# ET6801 register map
Vendor: ETMCU Inc.; File version: v0.0.1
CPU: CM7 r2p1, little endian, MPU, FPU, I-cache, D-cache, ITCM, DTCM, 4 interrupt priority bits
Registers are 32-bit, read-write, reset 0x0 unless marked. A register's access mark holds for its fields unless they carry their own. Offsets are from the block's base; [hi:lo] are bit positions; lines under a group give offsets from that group; {n}, {i} and the like mark numbered series; 'fields as' and 'values as' point back to an identical list.

## CLB — Provide an overview of the purpose and functionality of the peripheral: clb
Base 0x40022000
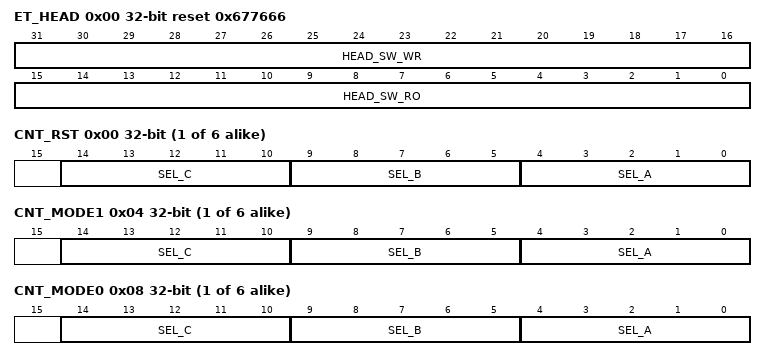
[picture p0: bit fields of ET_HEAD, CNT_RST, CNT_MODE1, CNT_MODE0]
0x00 ET_HEAD reset 0x677666
  [31:16] HEAD_SW_WR — 软件测试读写寄存器，硬件无访问
  [15:0] HEAD_SW_RO ro — 软件只读上报寄存器，硬件无访问,PID的ASICII 码表示
{0x4+0x12C*i} TILE_GRP[{i}] (i=0..5) group
  0x00 CNT_RST
    [14:10] SEL_C — CLB_CNT3模块计数器复位输入MUX选择信号。参见静态开关块输出多路复用表(CSB模块) 保护模式：EALLOW & LOCK 加载方式：静态加载
    [9:5] SEL_B — CLB_CNT2模块计数器复位输入MUX选择信号。参见静态开关块输出多路复用表(CSB模块) 保护模式：EALLOW & LOCK 加载方式：静态加载
    [4:0] SEL_A — CLB_CNT1模块计数器复位输入MUX选择信号。参见静态开关块输出多路复用表(CSB模块) 保护模式：EALLOW & LOCK 加载方式：静态加载
  0x04 CNT_MODE1
    [14:10] SEL_C — CLB_CNT3模块计数器Counter MODE_1输入MUX选择信号。参见静态开关块输出多路复用表(CSB模块) 保护模式：EALLOW & LOCK 加载方式：静态加载
    [9:5] SEL_B — CLB_CNT2模块计数器Counter MODE_1输入MUX选择信号。参见静态开关块输出多路复用表(CSB模块) 保护模式：EALLOW & LOCK 加载方式：静态加载
    [4:0] SEL_A — CLB_CNT1模块计数器Counter MODE_1输入MUX选择信号。参见静态开关块输出多路复用表(CSB模块) 保护模式：EALLOW & LOCK 加载方式：静态加载
  0x08 CNT_MODE0
    [14:10] SEL_C — CLB_CNT3模块计数器Counter MODE_0输入MUX选择信号。参见静态开关块输出多路复用表(CSB模块) 保护模式：EALLOW & LOCK 加载方式：静态加载
    [9:5] SEL_B — CLB_CNT2模块计数器Counter MODE_0输入MUX选择信号。参见静态开关块输出多路复用表(CSB模块) 保护模式：EALLOW & LOCK 加载方式：静态加载
    [4:0] SEL_A — CLB_CNT1模块计数器Counter MODE_0输入MUX选择信号。参见静态开关块输出多路复用表(CSB模块) 保护模式：EALLOW & LOCK 加载方式：静态加载
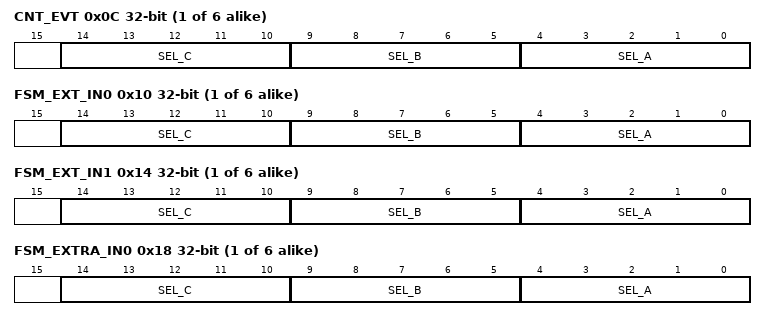
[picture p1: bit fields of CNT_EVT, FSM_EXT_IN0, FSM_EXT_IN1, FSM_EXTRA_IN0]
  0x0C CNT_EVT
    [14:10] SEL_C — CLB_CNT3模块计数器Counter EVENT输入MUX选择信号。参见静态开关块输出多路复用表(CSB模块) 保护模式：EALLOW & LOCK 加载方式：静态加载
    [9:5] SEL_B — CLB_CNT2模块计数器Counter EVENT输入MUX选择信号。参见静态开关块输出多路复用表(CSB模块) 保护模式：EALLOW & LOCK 加载方式：静态加载
    [4:0] SEL_A — CLB_CNT1模块计数器Counter EVENT输入MUX选择信号。参见静态开关块输出多路复用表(CSB模块) 保护模式：EALLOW & LOCK 加载方式：静态加载
  0x10 FSM_EXT_IN0
    [14:10] SEL_C — CLB_FSM3模块计数器FSM EXTERNAL_IN0输入MUX选择信号。参见静态开关块输出多路复用表(CSB模块) 保护模式：EALLOW & LOCK 加载方式：静态加载
    [9:5] SEL_B — CLB_ FSM 2模块计数器FSM EXTERNAL _IN0输入MUX选择信号。参见静态开关块输出多路复用表(CSB模块) 保护模式：EALLOW & LOCK 加载方式：静态加载
    [4:0] SEL_A — CLB_ FSM 1模块计数器FSM EXTERNAL _IN0输入MUX选择信号。参见静态开关块输出多路复用表(CSB模块) 保护模式：EALLOW & LOCK 加载方式：静态加载
  0x14 FSM_EXT_IN1
    [14:10] SEL_C — CLB_ FSM 3模块计数器FSM EXTERNAL_IN1输入MUX选择信号。参见静态开关块输出多路复用表(CSB模块) 保护模式：EALLOW & LOCK 加载方式：静态加载
    [9:5] SEL_B — CLB_ FSM 2模块计数器FSM EXTERNAL _IN1输入MUX选择信号。参见静态开关块输出多路复用表(CSB模块) 保护模式：EALLOW & LOCK 加载方式：静态加载
    [4:0] SEL_A — CLB_ FSM 1模块计数器FSM EXTERNAL _IN1输入MUX选择信号。参见静态开关块输出多路复用表(CSB模块) 保护模式：EALLOW & LOCK 加载方式：静态加载
  0x18 FSM_EXTRA_IN0
    [14:10] SEL_C — CLB_ FSM 3模块计数器FSM EXTRA_IN0输入MUX选择信号。参见静态开关块输出多路复用表(CSB模块) 保护模式：EALLOW & LOCK 加载方式：静态加载
    [9:5] SEL_B — CLB_ FSM 2模块计数器FSM EXTRA_IN0输入MUX选择信号。参见静态开关块输出多路复用表(CSB模块) 保护模式：EALLOW & LOCK 加载方式：静态加载
    [4:0] SEL_A — CLB_ FSM 1模块计数器FSM EXTRA_IN0输入MUX选择信号。参见静态开关块输出多路复用表(CSB模块) 保护模式：EALLOW & LOCK 加载方式：静态加载
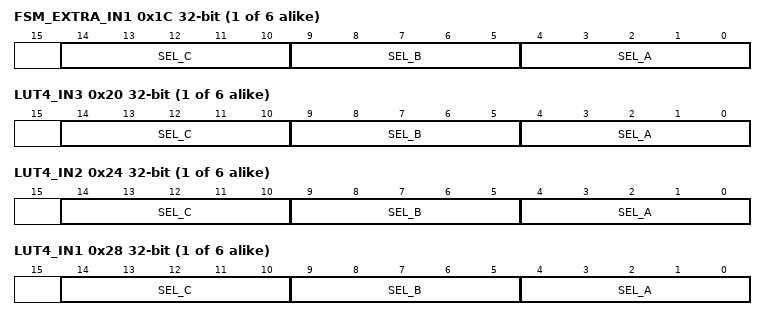
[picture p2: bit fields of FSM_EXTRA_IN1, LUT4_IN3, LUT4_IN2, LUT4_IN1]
  0x1C FSM_EXTRA_IN1
    [14:10] SEL_C — CLB_FSM3模块 EXTRA_IN1输入MUX选择信号。参见静态开关块输出多路复用表(CSB模块) 保护模式：EALLOW & LOCK 加载方式：静态加载
    [9:5] SEL_B — CLB_FSM2模块 EXTRA_IN1输入MUX选择信号。参见静态开关块输出多路复用表 保护模式：EALLOW & LOCK 加载方式：静态加载
    [4:0] SEL_A — CLB_FSM1模块 EXTRA_IN1输入MUX选择信号。参见静态开关块输出多路复用表(CSB模块) 保护模式：EALLOW & LOCK 加载方式：静态加载
  0x20 LUT4_IN3
    [14:10] SEL_C — CLB_LUT_3模块IN3输入MUX选择信号。参见静态开关块输出多路复用表(CSB模块) 保护模式：EALLOW & LOCK 加载方式：静态加载
    [9:5] SEL_B — CLB_LUT_2模块IN3输入MUX选择信号。参见静态开关块输出多路复用表(CSB模块) 保护模式：EALLOW & LOCK 加载方式：静态加载
    [4:0] SEL_A — CLB_LUT_1模块IN3输入MUX选择信号。参见静态开关块输出多路复用表(CSB模块) 保护模式：EALLOW & LOCK 加载方式：静态加载
  0x24 LUT4_IN2
    [14:10] SEL_C — CLB_LUT_3模块IN2输入MUX选择信号。参见静态开关块输出多路复用表 保护模式：EALLOW & LOCK 加载方式：静态加载
    [9:5] SEL_B — CLB_LUT_2模块IN2输入MUX选择信号。参见静态开关块输出多路复用表 保护模式：EALLOW & LOCK 加载方式：静态加载
    [4:0] SEL_A — CLB_LUT_1模块IN2输入MUX选择信号。参见静态开关块输出多路复用表 保护模式：EALLOW & LOCK 加载方式：静态加载
  0x28 LUT4_IN1
    [14:10] SEL_C — CLB_LUT_3模块IN1输入MUX选择信号。参见静态开关块输出多路复用表 保护模式：EALLOW & LOCK 加载方式：静态加载
    [9:5] SEL_B — CLB_LUT_2模块IN1输入MUX选择信号。参见静态开关块输出多路复用表 保护模式：EALLOW & LOCK 加载方式：静态加载
    [4:0] SEL_A — CLB_LUT_1模块IN1输入MUX选择信号。参见静态开关块输出多路复用表 保护模式：EALLOW & LOCK 加载方式：静态加载
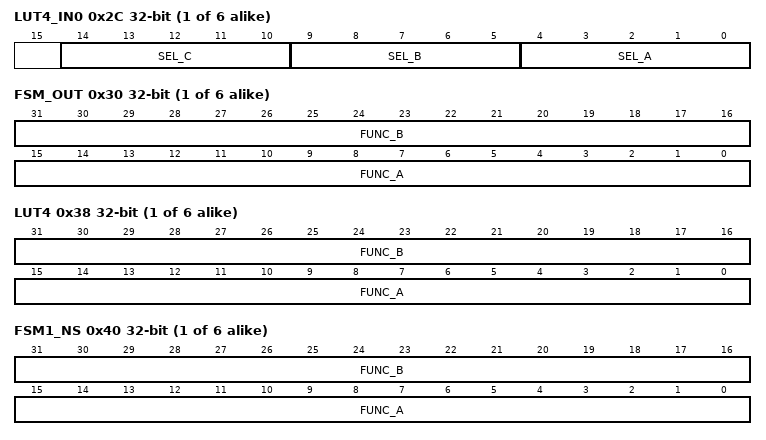
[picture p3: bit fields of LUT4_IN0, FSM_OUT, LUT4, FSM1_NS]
  0x2C LUT4_IN0
    [14:10] SEL_C — CLB_LUT_3模块IN0输入MUX选择信号。参见静态开关块输出多路复用表 保护模式：EALLOW & LOCK 加载方式：静态加载
    [9:5] SEL_B — CLB_LUT_2模块IN0输入MUX选择信号。参见静态开关块输出多路复用表 保护模式：EALLOW & LOCK 加载方式：静态加载
    [4:0] SEL_A — CLB_LUT_1模块IN0输入MUX选择信号。参见静态开关块输出多路复用表 保护模式：EALLOW & LOCK 加载方式：静态加载
  0x30 FSM_OUT
    [31:16] FUNC_B — CLB_FSM2模块OUTLUT输出函数配置 保护模式：EALLOW & LOCK 加载方式：静态加载
    [15:0] FUNC_A — CLB_FSM1模块OUTLUT输出函数配置 保护模式：EALLOW & LOCK 加载方式：静态加载
  0x34 FSM_OUT_FUNC
    [15:0] C — CLB_FSM3模块OUTLUT输出函数配置 保护模式：EALLOW & LOCK 加载方式：静态加载
  0x38 LUT4
    [31:16] FUNC_B — CLB_LUT2模块中输出函数配置 保护模式：EALLOW & LOCK 加载方式：静态加载
    [15:0] FUNC_A — CLB_LUT1模块中输出函数配置 保护模式：EALLOW & LOCK 加载方式：静态加载
  0x3C LUT4_FUNC
    [15:0] C — CLB_LUT3模块中输出函数配置 保护模式：EALLOW & LOCK 加载方式：静态加载
  0x40 FSM1_NS
    [31:16] FUNC_B — CLB_FSM1模块中 Nest State S1_LUT函数配置 保护模式：EALLOW & LOCK 加载方式：静态加载
    [15:0] FUNC_A — CLB_FSM1模块中 Nest State S0_LUT函数配置 保护模式：EALLOW & LOCK 加载方式：静态加载
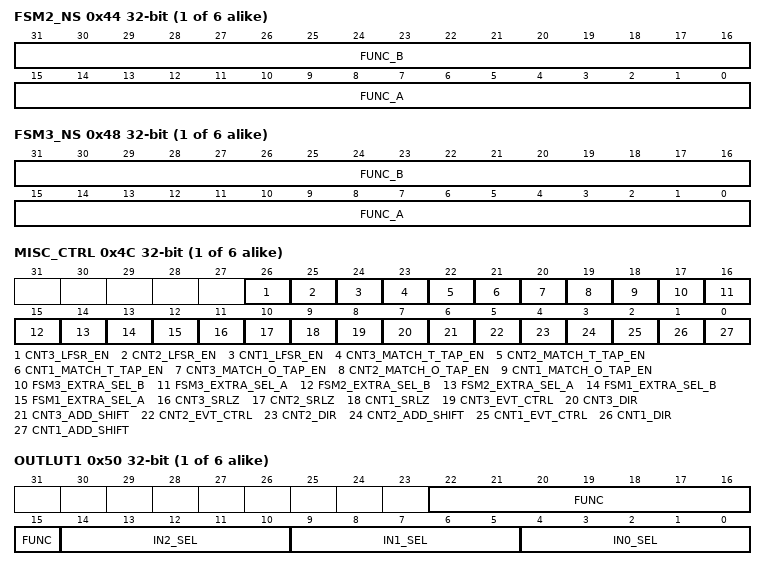
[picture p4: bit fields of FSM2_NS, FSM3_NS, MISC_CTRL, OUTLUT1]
  0x44 FSM2_NS
    [31:16] FUNC_B — CLB_FSM2模块中 Nest State S1_LUT函数配置 保护模式：EALLOW & LOCK 加载方式：静态加载
    [15:0] FUNC_A — CLB_FSM2模块中Nest State S0_LUT函数配置 保护模式：EALLOW & LOCK 加载方式：静态加载
  0x48 FSM3_NS
    [31:16] FUNC_B — CLB_FSM3模块中Nest State S1_LUT函数配置 保护模式：EALLOW & LOCK 加载方式：静态加载
    [15:0] FUNC_A — CLB_FSM3模块中Nest State S0_LUT函数配置 保护模式：EALLOW & LOCK 加载方式：静态加载
  0x4C MISC_CTRL
    [26] CNT3_LFSR_EN — 在计数器3为SERIALIZER模式的前提下，决定计数器是否为LFSR模式。 'b0 = 不采用LFSR模式 'b1 = 采用LFSR模式 保护模式：EALLOW & LOCK 加载方式：静态加载
    [25] CNT2_LFSR_EN — 在计数器2为SERIALIZER模式的前提下，决定计数器是否为LFSR模式。 'b0 = 不采用LFSR模式 'b1 = 采用LFSR模式 保护模式：EALLOW & LOCK 加载方式：静态加载
    [24] CNT1_LFSR_EN — 在计数器1为SERIALIZER模式的前提下，决定计数器是否为LFSR模式。 'b0 = 不采用LFSR模式 'b1 = 采用LFSR模式 保护模式：EALLOW & LOCK 加载方式：静态加载
    [23] CNT3_MATCH_T_TAP_EN — 决定计数器3 Match 2输出信号来源 'b0 =来自计数器和Match2 REF对比结果; 'b1 = 由match1_tap_val决定的计数器某个bit 保护模式：EALLOW & LOCK 加载方式：静态加载
    [22] CNT2_MATCH_T_TAP_EN — 决定计数器2 Match 2输出信号来源 'b0 =来自计数器和Match2 REF对比结果; 'b1 = 由match1_tap_val决定的计数器某个bit 保护模式：EALLOW & LOCK 加载方式：静态加载
    [21] CNT1_MATCH_T_TAP_EN — 决定计数器1 Match 2输出信号来源 'b0 =来自计数器和Match2 REF对比结果; 'b1 = 由match1_tap_val决定的计数器某个bit 保护模式：EALLOW & LOCK 加载方式：静态加载
    [20] CNT3_MATCH_O_TAP_EN — 决定计数器3 Match 1输出信号来源 'b0 =来自计数器和Match1 REF对比结果; 'b1 = 由match1_tap_val决定的计数器某个bit 保护模式：EALLOW & LOCK 加载方式：静态加载
    [19] CNT2_MATCH_O_TAP_EN — 决定计数器2 Match 1输出信号来源 'b0 =来自计数器和Match1 REF对比结果; 'b1 = 由match1_tap_val决定的计数器某个bit 保护模式：EALLOW & LOCK 加载方式：静态加载
    [18] CNT1_MATCH_O_TAP_EN — 决定计数器1 Match 1输出信号来源 'b0 =来自计数器和Match1 REF对比结果; 'b1 = 由match1_tap_val决定的计数器某个bit 保护模式：EALLOW & LOCK 加载方式：静态加载
    [17] FSM3_EXTRA_SEL_B — 选择FSM3 OUTLUT的输入信号 'b0 = FSM OUTLUT输入信号来自 S1; 'b1 = FSM OUTLUT输入信号来自EXTRA_EXT_IN1 保护模式：EALLOW & LOCK 加载方式：静态加载
    [16] FSM3_EXTRA_SEL_A — 选择FSM3 OUTLUT的输入信号 'b0 = FSM OUTLUT输入信号来自 S0; 'b1 = FSM OUTLUT输入信号来自EXTRA_EXT_IN0 保护模式：EALLOW & LOCK 加载方式：静态加载
    [15] FSM2_EXTRA_SEL_B — 选择FSM2 OUTLUT的输入信号 'b0 = FSM OUTLUT输入信号来自 S1; 'b1 = FSM OUTLUT输入信号来自EXTRA_EXT_IN1 保护模式：EALLOW & LOCK 加载方式：静态加载
    [14] FSM2_EXTRA_SEL_A — 选择FSM2 OUTLUT的输入信号 'b0 = FSM LUT输入信号来自 S0; 'b1 = FSM LUT输入信号来自EXTRA_EXT_IN0 保护模式：EALLOW & LOCK 加载方式：静态加载
    [13] FSM1_EXTRA_SEL_B — 选择FSM1 OUTLUT的输入信号 'b0 = FSM LUT输入信号来自 S1; 'b1 = FSM LUT输入信号来自EXTRA_EXT_IN1 保护模式：EALLOW & LOCK 加载方式：静态加载
    [12] FSM1_EXTRA_SEL_A — 选择FSM1 OUTLUT的输入信号 'b0 = FSM LUT输入信号来自 S0; 'b1 = FSM LUT输入信号来自EXTRA_EXT_IN0 保护模式：EALLOW & LOCK 加载方式：静态加载
    [11] CNT3_SRLZ — 控制CLB_CNT3模块计数器是否处于Serializer模式 'b0 = CLB_CNT3模块计数器不处于Serializer模式; 'b1 = CLB_CNT3模块计数器处于Serializer模式 保护模式：EALLOW & LOCK 加载方式：静态加载
    [10] CNT2_SRLZ — 控制CLB_CNT2模块计数器是否处于Serializer模式 'b0 = CLB_CNT2模块计数器不处于Serializer模式; 'b1 = CLB_CNT2模块计数器处于Serializer模式 保护模式：EALLOW & LOCK 加载方式：静态加载
    [9] CNT1_SRLZ — 控制CLB_CNT1模块计数器是否处于Serializer模式 'b0 = CLB_CNT1模块计数器不处于Serializer模式; 'b1 = CLB_CNT1模块计数器处于Serializer模式 保护模式：EALLOW & LOCK 加载方式：静态加载
    [8] CNT3_EVT_CTRL — 控制 CNT3 事件发生时计数器的操作。 'b0 = 不加法或移位，但加载预定义值 'b1 = 基于其他位，与预定义值相加/移位 保护模式：EALLOW & LOCK 加载方式：静态加载，该位必须为0，间接加载和计数器的HLC加载才能生效。
    [7] CNT3_DIR — 控制CNT3的加法/移位方向 'b0 = 右移或减去 'b1 = 左移或添加 保护模式：EALLOW & LOCK 加载方式：静态加载
    [6] CNT3_ADD_SHIFT — 控制CNT2计数器在事件发生时进行加法还是移位。 'b0 = 移位 'b1 = ADD 保护模式：EALLOW & LOCK 加载方式：静态加载
    [5] CNT2_EVT_CTRL — 控制 CNT2事件发生时计数器的操作。'b0 = 不加法或移位，但加载预定义值，此时为间接加载 'b1 = 基于其他位，与预定义值相加/移位 保护模式：EALLOW & LOCK 加载方式：静态，该位必须为0，间接加载和计数器的HLC加载才能生效。
    [4] CNT2_DIR — 控制CNT2的加法/移位方向 'b0 = 右移或减去 'b1 = 左移或添加 保护模式：EALLOW & LOCK 加载方式：静态加载
    [3] CNT2_ADD_SHIFT — 控制CNT1计数器在事件发生时进行加法还是移位。 'b0 = 移位 'b1 = ADD 保护模式：EALLOW & LOCK 加载方式：静态加载
    [2] CNT1_EVT_CTRL — 控制 CNT1事件发生时计数器的操作。 'b0 = 不加法或移位，但加载预定义值 'b1 = 基于其他位，与预定义值相加/移位 保护模式：EALLOW & LOCK 加载方式：静态，该位必须为0，间接加载和计数器的HLC加载才能生效。
    [1] CNT1_DIR — 控制 CNT1 的加法/移位方向 'b0 = 右移或减去 'b1 = 左移或添加 保护模式：EALLOW &LOCK 加载方式：静态加载
    [0] CNT1_ADD_SHIFT — 控制CLB_CNT1模块计数器在事件发生时进行加法还是移位。 'b0 = 移位 'b1 = ADD 保护模式：EALLOW & LOCK 加载方式：静态加载
  0x50 OUTLUT1
    [22:15] FUNC — outputLUT输出函数
    [14:10] IN2_SEL — outputLUT_IN2 MUX选择信号。参见静态开关块输出多路复用表 保护模式：EALLOW & LOCK 加载方式：静态加载
    [9:5] IN1_SEL — outputLUT_IN1 MUX选择信号。参见静态开关块输出多路复用表 保护模式：EALLOW & LOCK 加载方式：静态加载
    [4:0] IN0_SEL — outputLUT_IN0 MUX选择信号。参见静态开关块输出多路复用表 保护模式：EALLOW & LOCK 加载方式：静态加载
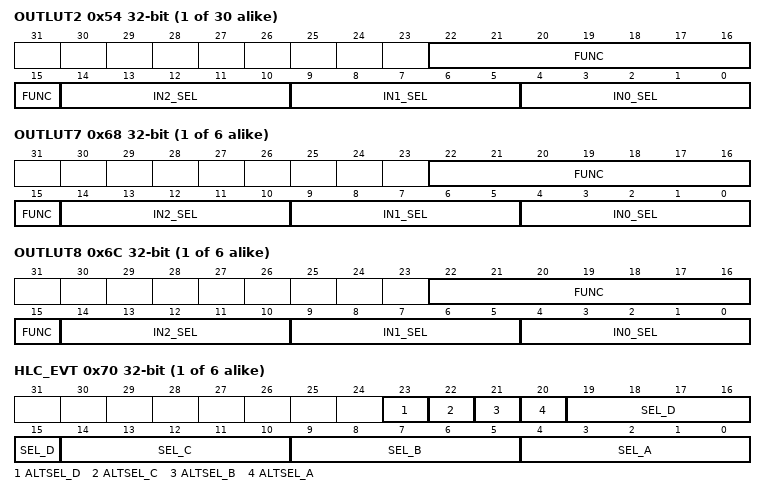
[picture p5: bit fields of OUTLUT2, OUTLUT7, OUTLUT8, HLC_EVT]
  {0x4C+4j} OUTLUT{j} (j=2..6)
    [22:15] FUNC — outputLUT输出函数
    [14:10] IN2_SEL — outputLUT{j}_IN2 MUX选择信号。参见静态开关块输出多路复用表 保护模式：EALLOW & LOCK 加载方式：静态加载
    [9:5] IN1_SEL — outputLUT{j}_IN1 MUX选择信号。参见静态开关块输出多路复用表 保护模式：EALLOW & LOCK 加载方式：静态加载
    [4:0] IN0_SEL — outputLUT{j}_IN0 MUX选择信号。参见静态开关块输出多路复用表 保护模式：EALLOW & LOCK 加载方式：静态加载
  0x68 OUTLUT7
    fields as TILE_GRP[0].OUTLUT1
  0x6C OUTLUT8
    fields as TILE_GRP[0].OUTLUT1
  0x70 HLC_EVT
    [23] ALTSEL_D — EVENT3另一组选择信号 'b0 = 从静态开关复用表中选择 'b1 = 从静态开关复用备选表中选择 保护模式：EALLOW & LOCK
    [22] ALTSEL_C — EVENT2另一组选择信号 'b0 = 从静态开关复用表中选择 'b1 = 从静态开关复用备选表中选择 保护模式：EALLOW & LOCK
    [21] ALTSEL_B — EVENT1另一组选择信号 'b0 = 从静态开关复用表中选择 'b1 = 从静态开关复用备选表中选择 保护模式：EALLOW & LOCK
    [20] ALTSEL_A — EVENT0另一组选择信号 'b0 = 从静态开关复用表中选择 'b1 = 从静态开关复用备选表中选择 保护模式：EALLOW & LOCK
    [19:15] SEL_D — HLC EVENT3输入MUX选择信号。参见静态开关块输出多路复用表 保护模式：EALLOW & LOCK 加载方式：静态加载
    [14:10] SEL_C — HLC EVENT2输入MUX选择信号。参见静态开关块输出多路复用表 保护模式：EALLOW & LOCK 加载方式：静态加载
    [9:5] SEL_B — HLC EVENT1输入MUX选择信号。参见静态开关块输出多路复用表 保护模式：EALLOW & LOCK 加载方式：静态加载
    [4:0] SEL_A — HLC EVENT0输入MUX选择信号。参见静态开关块输出多路复用表 保护模式：EALLOW & LOCK 加载方式：静态加载
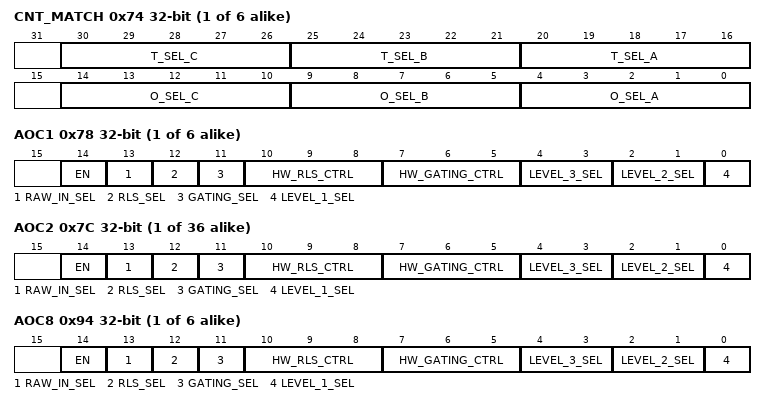
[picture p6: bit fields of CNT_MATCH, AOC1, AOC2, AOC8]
  0x74 CNT_MATCH
    [30:26] T_SEL_C — match2选择计数器2某一比特作为输出的MUX选择信号。 match1 = cnt1[cfg_cnt_match_t_sel_c]; 保护模式：EALLOW & LOCK 加载方式：静态加载
    [25:21] T_SEL_B — match2选择计数器1某一比特作为输出的MUX选择信号。 match1 = cnt1[cfg_cnt_match_t_sel_b]; 保护模式：EALLOW & LOCK 加载方式：静态加载
    [20:16] T_SEL_A — match2选择计数器0某一比特作为输出的MUX选择信号。 match1 = cnt1[cfg_cnt_match_t_sel_a]; 保护模式：EALLOW & LOCK 加载方式：静态加载
    [14:10] O_SEL_C — match1选择计数器2某一比特作为输出的MUX选择信号。 match1 = cnt1[cfg_cnt_match_o_sel_c]; 保护模式：EALLOW & LOCK 加载方式：静态加载
    [9:5] O_SEL_B — match1选择计数器1某一比特作为输出的MUX选择信号。 match1 = cnt1[cfg_cnt_match_o_sel_b]; 保护模式：EALLOW & LOCK 加载方式：静态加载
    [4:0] O_SEL_A — match1选择计数器0某一比特作为输出的MUX选择信号, match1 = cnt1[cfg_cnt_match_o_sel_a]; 保护模式：EALLOW & LOCK 加载方式：静态加载
  0x78 AOC1
    [14] EN — 选择CELL_output输入信号经过AOC多级处理或者直接bypass 'b0 = bypass 'b1 = enable AOC模块 加载方式：动态加载
    [13] RAW_IN_SEL — 选择AOC1模块的输入 'b0 = outlut_output1（打一拍）作为输入 'b1 =bdry_in_a作为输入 保护模式：EALLOW & LOCK 加载方式：动态加载
    [12] RLS_SEL — 选择HW(CELL outputs)或SW(GP_REG)作为release的控制信号 'b0 = SW寄存器值作为release的控制信号 'b1 = CELL outputs作为release控制信号 保护模式：EALLOW & LOCK 加载方式：动态加载
    [11] GATING_SEL — 选择HW(CELL outputs)或SW(GP_REG)作为gating的控制信号 'b0 = SW寄存器值作为gating的控制信号 'b1 = CELL outputs作为gating控制信号 保护模式：EALLOW & LOCK 加载方式：动态加载
    [10:8] HW_RLS_CTRL — AOC level3 阶段选择1bit CLB_OUTLUT作为控制信号。 该值从0到7分别对应outlut1~8的输出 加载方式：静态加载
    [7:5] HW_GATING_CTRL — AOC level2 阶段选择1bit CLB_OUTLUT作为控制信号。 该值从0到7分别对应outlut1~8的输出 保护模式：EALLOW & LOCK 加载方式：静态加载
    [4:3] LEVEL_3_SEL — 第二级MUX选择信号。 'b00 = 原信号输出 'b01 = 输入控制信号拉高会导致输出的清除 'b10= 输入控制信号的上升沿会导致输出的置位 'b11 = 输入信号打一拍后输出 保护模式：EALLOW & LOCK 加载方式：静态加载
    [2:1] LEVEL_2_SEL — 第二级MUX选择信号。 'b00 = 原信号输入至下一级 'b01 = (上一级输入信号&gating_control ) 输入至下一级 'b10= (上一级输入信号|gating_control ) 输入至下一级 'b11 = (上一级输入信号^gating_control )输入至下一级 保护模式：EALLOW & LOCK 加载方式：静态加载
    [0] LEVEL_1_SEL — 第一级MUX选择信号。 'b0 = 原信号输入至下一级 'b1 = 信号翻转后输入至下一级 保护模式：EALLOW & LOCK 加载方式：静态加载
  {0x74+4j} AOC{j} (j=2..7)
    [14] EN — 选择CELL_output输入信号经过AOC多级处理或者直接bypass 'b0 = bypass 'b1 = enable AOC模块 加载方式：动态加载
    [13] RAW_IN_SEL — 选择AOC模块的输入 'b0 = CELL_output（打一拍）作为输入 'b1 = CELL inputs作为输入 保护模式：EALLOW & LOCK 加载方式：动态加载
    [12] RLS_SEL — 选择HW(CELL outputs)或SW(GP_REG)作为release的控制信号 'b0 = SW寄存器值作为release的控制信号 'b1 = CELL outputs作为release控制信号 保护模式：EALLOW & LOCK 加载方式：动态加载
    [11] GATING_SEL — 选择HW(CELL outputs)或SW(GP_REG)作为gating的控制信号 'b0 = SW寄存器值作为gating的控制信号 'b1 = CELL outputs作为gating控制信号 保护模式：EALLOW & LOCK 加载方式：动态加载
    [10:8] HW_RLS_CTRL — AOC level3 阶段选择1bit CLB_OUTLUT作为控制信号。 该值从0到7分别对应outlut1~8的输出 加载方式：静态加载
    [7:5] HW_GATING_CTRL — AOC level2 阶段选择1bit CLB_OUTLUT作为控制信号。 该值从0到7分别对应outlut1~8的输出 保护模式：EALLOW & LOCK 加载方式：静态加载
    [4:3] LEVEL_3_SEL — 第二级MUX选择信号。 'b00 = 原信号输出 'b01 = 输入控制信号拉高会导致输出的清除 'b10= 输入控制信号的上升沿会导致输出的置位 'b11 = 输入信号打一拍后输出 保护模式：EALLOW & LOCK 加载方式：静态加载
    [2:1] LEVEL_2_SEL — 第二级MUX选择信号。 'b00 = 原信号输入至下一级 'b01 = (上一级输入信号&gating_control ) 输入至下一级 'b10= (上一级输入信号|gating_control ) 输入至下一级 'b11 = (上一级输入信号^gating_control )输入至下一级 保护模式：EALLOW & LOCK 加载方式：静态加载
    [0] LEVEL_1_SEL — 第一级MUX选择信号。 'b0 = 原信号输入至下一级 'b1 = 信号翻转后输入至下一级 保护模式：EALLOW & LOCK 加载方式：静态加载
  0x94 AOC8
    [14] EN — 选择CELL_output输入信号经过AOC多级处理或者直接bypass 'b0 = bypass 'b1 = enable AOC模块 加载方式：静态加载
    [13] RAW_IN_SEL — 选择AOC模块的输入 'b0 = CELL_output（打一拍）作为输入 'b1 = CELL inputs作为输入 保护模式：EALLOW & LOCK 加载方式：静态加载
    [12] RLS_SEL — 选择HW(CELL outputs)或SW(GP_REG)作为release的控制信号 'b0 = SW寄存器值作为release的控制信号 'b1 = CELL outputs作为release控制信号 保护模式：EALLOW & LOCK 加载方式：静态加载
    [11] GATING_SEL — 选择HW(TILE outputs)或SW作为gating的控制信号 'b0 = SW寄存器值作为gating的控制信号 'b1 = TILE outputs作为gating控制信号 保护模式：EALLOW & LOCK 加载方式：静态加载
    [10:8] HW_RLS_CTRL — 从8个CLB_OUTLUT中选择一个作为rls的控制信号； 'b000 = clb_outlut1_output 'b001 = clb_outlut2_output ... 'b111 = clb_outlut8_output 保护模式：EALLOW & LOCK 加载方式：静态加载
    [7:5] HW_GATING_CTRL — 从8个CLB_OUTLUT中选择一个作为gating的控制信号； 'b000 = clb_outlut1_output 'b001 = clb_outlut2_output ... 'b111 = clb_outlut8_output 保护模式：EALLOW & LOCK 加载方式：静态加载
    [4:3] LEVEL_3_SEL — 第二级MUX选择信号。 'b00 = 原信号输出 'b01 = 输入控制信号拉高会导致输出的清除 'b10= 输入控制信号的上升沿会导致输出的置位 'b11 = 输入信号打一拍后输出 保护模式：EALLOW & LOCK 加载方式：静态加载
    [2:1] LEVEL_2_SEL — 第二级MUX选择信号。 'b00 = 原信号输入至下一级 'b01 = (上一级输入信号&gating_control ) 输入至下一级 'b10= (上一级输入信号|gating_control ) 输入至下一级 'b11 = (上一级输入信号^gating_control )输入至下一级 保护模式：EALLOW & LOCK 加载方式：静态加载
    [0] LEVEL_1_SEL — 第一级MUX选择信号。 'b0 = 原信号输入至下一级 'b1 = 信号翻转后输入至下一级 保护模式：EALLOW & LOCK 加载方式：静态加载
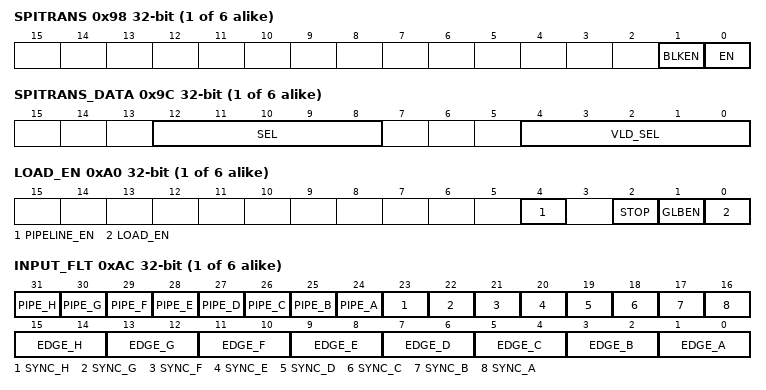
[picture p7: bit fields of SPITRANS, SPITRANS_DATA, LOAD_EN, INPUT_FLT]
  0x98 SPITRANS
    [1] BLKEN — 该阻止对CFG_CLB_OUT_EN的写入； 'b0 = CFG_CLB_OUT_EN起作用； 'b1 = CFG_CLB_OUT_EN被屏蔽； 保护模式：EALLOW & LOCK 加载方式：静态加载
    [0] EN — 使能SPI_DataTrans模式； 'b0 = 不使能 'b1 = 使能通用寄存器GR_A的值可以传输到SPIbuffer中 保护模式：EALLOW & LOCK 加载方式：静态加载
  0x9C SPITRANS_DATA
    [12:8] SEL — 选择R0发送到SPIbuffer的16比特数据； 'b 00000 Output data is R0[15:0] 'b 00001 Output data is R0[16:1] 'b 00010 Output data is R0[17:2] 'b 00011 Output data is R0[18:3] ... 保护模式：EALLOW & LOCK 加载方式：静态加载
    [4:0] VLD_SEL — 在CSB中选择一个信号作为将GR_A数据发送到SPIbuffer的数据有效信号，参见静态开关块输出多路复用表 保护模式：EALLOW & LOCK 加载方式：静态加载
  0xA0 LOAD_EN
    [4] PIPELINE_EN — 该位计数器模块中的pipelining模式，不开启时，计数器模块执行加法时为load+cnt_val；开启后计数器执行加法为load+last_cnt_val，并在下一拍写入计数器寄存器中。 设置为1使能流水操作 保护模式：无 加载方式：静态加载
    [2] STOP — 该位定义 CPU 调试 HALT 期间 CELL 中sequential elements的行为。如果该位设置为 0，则调试 HALT 条件被忽略 'b0 = CLB正常运行 'b1 = CLB内部运算暂停； 保护模式：无 加载方式：动态加载
    [1] GLBEN — 该位是 CELL 逻辑的全局使能信号。这也是 CELL 逻辑的软复位。当该位从 1 清零到 0 时，CLB 输出（包括 LUT 和 OUTLUT）将被门控，即当 GLOBAL_EN 为低电平时，CLB 输出为低电平。此外，FSM 和 AOC 块也将被重置。需要注意的是，当该位变为低电平时，COUNTER 模块和 HLC 将停止运行，但内部不会重置。这样就可以在 GLOBAL_EN 为 0 时预载这些子模块。全局使能在完成所有其他配置设置。 保护模式：LOCK 加载方式：动态加载
    [0] LOAD_EN — 将该位设置为 "1 "时，将产生一个脉冲使能tile中的 间接寄存器 加载数据 保护模式：无 加载方式：动态加载
  0xA4 LOAD_ADDR
    [5:0] VALUE — 间接加载时的地址。 保护模式：无 加载方式：动态加载
  0xA8 LOAD_DATA
    [31:0] VALUE — 间接加载时的数据。 保护模式：无 加载方式：动态加载
  0xAC INPUT_FLT
    [31] PIPE_H — CELL INPUT[7] pipeline 'b0 = bypass 'b1 = 输入信号经过flop被打一拍 保护模式：LOCK 加载方式：静态加载
    [30] PIPE_G — CELL INPUT[6] pipeline 'b0 = bypass 'b1 = 输入信号经过flop被打一拍 保护模式：LOCK 加载方式：静态加载
    [29] PIPE_F — CELL INPUT[5] pipeline 'b0 = bypass 'b1 = 输入信号经过flop被打一拍 保护模式：LOCK 加载方式：静态加载
    [28] PIPE_E — CELL INPUT[4] pipeline 'b0 = bypass 'b1 = 输入信号经过flop被打一拍 保护模式：LOCK 加载方式：静态加载
    [27] PIPE_D — CELL INPUT[3] pipeline 'b0 = bypass 'b1 = 输入信号经过flop被打一拍 保护模式：LOCK 加载方式：静态加载
    [26] PIPE_C — CELL INPUT[2] pipeline 'b0 = bypass 'b1 = 输入信号经过flop被打一拍 保护模式：LOCK 加载方式：静态加载
    [25] PIPE_B — CELL INPUT[1] pipeline 'b0 = bypass 'b1 = 输入信号经过flop被打一拍 保护模式：LOCK 加载方式：静态加载
    [24] PIPE_A — CELL INPUT[0] pipeline 'b0 = bypass 'b1 = 输入信号经过flop被打一拍 保护模式： LOCK 加载方式：静态加载
    [23] SYNC_H — CELL INPUT[7] 同步器控制 'b0 = bypass 'b1 = 输入信号被同步处理 保护模式：LOCK 加载方式：静态加载
    [22] SYNC_G — CELL INPUT[6] 同步器控制 'b0 = bypass 'b1 = 输入信号被同步处理 保护模式：LOCK 加载方式：静态加载
    [21] SYNC_F — CELL INPUT[5] 同步器控制 'b0 = bypass 'b1 = 输入信号被同步处理 保护模式：LOCK 加载方式：静态加载
    [20] SYNC_E — CELL INPUT[4] 同步器控制 'b0 = bypass 'b1 = 输入信号被同步处理 保护模式：LOCK 加载方式：静态加载
    [19] SYNC_D — CELL INPUT[3] 同步器控制 'b0 = bypass 'b1 = 输入信号被同步处理 保护模式：LOCK 加载方式：静态加载
    [18] SYNC_C — CELL INPUT[2] 同步器控制 'b0 = bypass 'b1 = 输入信号被同步处理 保护模式：LOCK 加载方式：静态加载
    [17] SYNC_B — CELL INPUT[1] 同步器控制 'b0 = bypass 'b1 = 输入信号被同步处理 保护模式：LOCK 加载方式：静态加载
    [16] SYNC_A — CELL INPUT[0] 同步器控制 'b0 = bypass 'b1 = 输入信号被同步处理 保护模式：LOCK 加载方式：静态加载
    [15:14] EDGE_H — CELL INPUT[7] filter选择，用于边沿检测 'b00 = bypass 'b01 = 上升沿检测 'b10 = 下降沿检测 'b11 = 边沿检测 保护模式：LOCK 加载方式：静态加载
    [13:12] EDGE_G — CELL INPUT[6] filter选择，用于边沿检测 'b00 = bypass 'b01 = 上升沿检测 'b10 = 下降沿检测 'b11 = 边沿检测 保护模式：LOCK 加载方式：静态加载
    [11:10] EDGE_F — CELL INPUT[5] filter选择，用于边沿检测 'b00 = bypass 'b01 = 上升沿检测 'b10 = 下降沿检测 'b11 = 边沿检测 保护模式：LOCK 加载方式：静态加载
    [9:8] EDGE_E — CELL INPUT[4] filter选择，用于边沿检测 'b00 = bypass 'b01 = 上升沿检测 'b10 = 下降沿检测 'b11 = 边沿检测 保护模式：LOCK 加载方式：静态加载
    [7:6] EDGE_D — CELL INPUT[3] filter选择，用于边沿检测 'b00 = bypass 'b01 = 上升沿检测 'b10 = 下降沿检测 'b11 = 边沿检测 保护模式：LOCK 加载方式：静态加载
    [5:4] EDGE_C — CELL INPUT[2] filter选择，用于边沿检测 'b00 = bypass 'b01 = 上升沿检测 'b10 = 下降沿检测 'b11 = 边沿检测 保护模式：LOCK 加载方式：静态加载
    [3:2] EDGE_B — CELL INPUT[1] filter选择，用于边沿检测 'b00 = bypass 'b01 = 上升沿检测 'b10 = 下降沿检测 'b11 = 边沿检测 保护模式：LOCK 加载方式：静态加载
    [1:0] EDGE_A — CELL INPUT[0] filter选择，边沿检测 'b00 = bypass 'b01 = 上升沿检测 'b10 = 下降沿检测 'b11 = 边沿检测 保护模式：LOCK 加载方式：静态加载
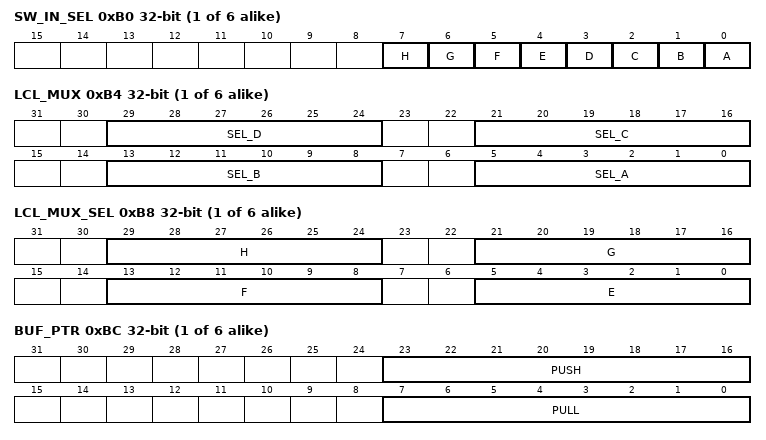
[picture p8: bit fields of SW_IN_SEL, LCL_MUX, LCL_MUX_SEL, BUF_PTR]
  0xB0 SW_IN_SEL
    [7] H — 选择CELL INPUT[7]来自外部输入还是来自CFG_SW[7] 'b0 = 来自外部输入 'b1 = 来自cfg_sw_input_h 保护模式：LOCK 加载方式：静态加载
    [6] G — 选择CELL INPUT[6]来自外部输入还是来自CFG_SW[6] 'b0 = 来自外部输入 'b1 = 来自cfg_sw_input_g 保护模式：LOCK 加载方式：静态加载
    [5] F — 选择CELL INPUT[5]来自外部输入还是来自CFG_SW[5] 'b0 = 来自外部输入 'b1 = 来自cfg_sw_input_f 保护模式：LOCK 加载方式：静态加载
    [4] E — 选择CELL INPUT[4]来自外部输入还是来自软件输入； 'b0 = 来自外部输入 'b1 = 来自cfg_sw_input_e 保护模式：LOCK 加载方式：静态加载
    [3] D — 选择CELL INPUT[3]来自外部输入还是来自软件输入； 'b0 = 来自外部输入 'b1 = 来自cfg_sw_input_d 保护模式：LOCK 加载方式：静态加载
    [2] C — 选择CELL INPUT[2]来自外部输入还是来自软件输入； 'b0 = 来自外部输入 'b1 = 来自cfg_sw_input_c 保护模式：LOCK 加载方式：静态加载
    [1] B — 选择CELL INPUT[1]来自外部输入还是来自软件输入； 'b0 = 来自外部输入 'b1 = 来自cfg_sw_input_b 保护模式：LOCK 加载方式：静态加载
    [0] A — 选择CELL INPUT[0]来自外部输入还是来自软件输入； 'b0 = 来自外部输入 'b1 = 来自cfg_sw_input_a 保护模式：LOCK 加载方式：静态加载
  0xB4 LCL_MUX
    [29:24] SEL_D — INPUT3 6比特MUX选择信号，参见本地信号多路复用表 保护模式：LOCK 加载方式：静态加载
    [21:16] SEL_C — INPUT2 6比特MUX选择信号，参见本地信号多路复用表 保护模式：LOCK 加载方式：静态加载
    [13:8] SEL_B — INPUT1 6比特MUX选择信号，参见本地信号多路复用表 保护模式：LOCK 加载方式：静态加载
    [5:0] SEL_A — INPUT0 6比特MUX选择信号，参见本地信号多路复用表 保护模式：LOCK 加载方式：静态加载
  0xB8 LCL_MUX_SEL
    [29:24] H — INPUT3 6比特MUX选择信号，参见本地信号多路复用表 保护模式：LOCK 加载方式：静态加载
    [21:16] G — INPUT2 6比特MUX选择信号，参见本地信号多路复用表 保护模式：LOCK 加载方式：静态加载
    [13:8] F — INPUT1 6比特MUX选择信号，参见本地信号多路复用表 保护模式：LOCK 加载方式：静态加载
    [5:0] E — INPUT0 6比特MUX选择信号，参见本地信号多路复用表 保护模式：LOCK 加载方式：静态加载
  0xBC BUF_PTR
    [23:16] PUSH — clb_tile数据交换模块的fifo指针。push表示从HLC模块写入到4-word fifo。到达0xff归零其中低2比特表示操作中的实际指针。
    [7:0] PULL — 数据交换模块的fifo指针。pull表示从4-word fifo写入到HLC模块。
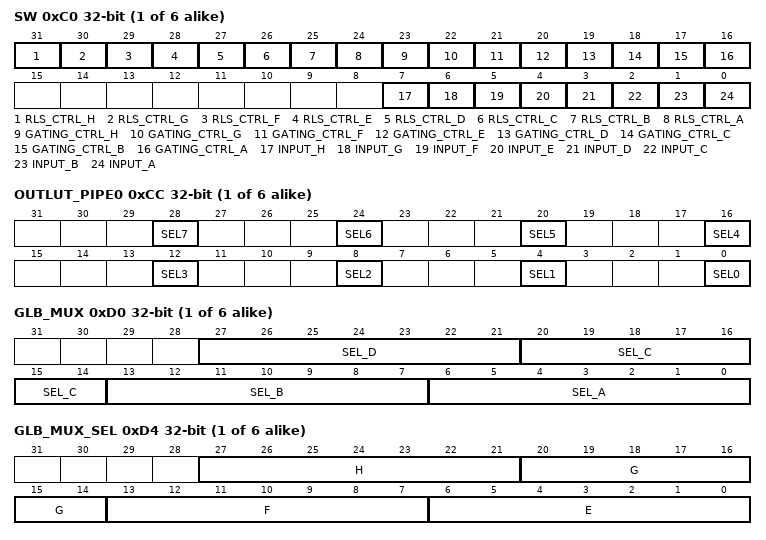
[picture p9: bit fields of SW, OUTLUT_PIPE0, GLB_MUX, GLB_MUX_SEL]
  0xC0 SW
    [31] RLS_CTRL_H — AOC8模块中output1软件release控制 保护模式：无 加载方式：动态加载
    [30] RLS_CTRL_G — AOC7模块中output1软件release控制 保护模式：无 加载方式：动态加载
    [29] RLS_CTRL_F — AOC6模块中output1软件release控制 保护模式：无 加载方式：动态加载
    [28] RLS_CTRL_E — AOC5模块中output1软件release控制 保护模式：无 加载方式：动态加载
    [27] RLS_CTRL_D — AOC4模块中output1软件release控制 保护模式：无 加载方式：动态加载
    [26] RLS_CTRL_C — AOC3模块中output1软件release控制 保护模式：无 加载方式：动态加载
    [25] RLS_CTRL_B — AOC2模块中output1软件release控制 保护模式：无 加载方式：动态加载
    [24] RLS_CTRL_A — AOC1模块中output软件release控制 保护模式：无 加载方式：动态加载
    [23] GATING_CTRL_H — AOC模块中output软件gating 控制 保护模式：无 加载方式：动态加载
    [22] GATING_CTRL_G — AOC模块中outpu软件gating 控制 保护模式：无 加载方式：动态加载
    [21] GATING_CTRL_F — AOC模块中outpu软件gating 控制 保护模式：无 加载方式：动态加载
    [20] GATING_CTRL_E — AOC模块中outpu软件gating 控制 保护模式：无 加载方式：动态加载
    [19] GATING_CTRL_D — AOC模块中outpu软件gating 控制 保护模式：无 加载方式：动态加载
    [18] GATING_CTRL_C — AOC模块中outpu软件gating 控制 保护模式：无 加载方式：动态加载
    [17] GATING_CTRL_B — AOC模块中output1软件gating 控制 保护模式：无 加载方式：动态加载
    [16] GATING_CTRL_A — AOC模块中output1软件gating 控制 保护模式：无 加载方式：动态加载
    [7] INPUT_H — CPU配置的值，由cfg_clb_in_sel_h选择可直接作为CLB模块clb_bdry_in_h的输入 保护模式：无 加载方式：动态加载
    [6] INPUT_G — CPU配置的值，由cfg_clb_in_sel_h选择可直接作为CLB模块clb_bdry_in_h的输入 保护模式：无 加载方式：动态加载
    [5] INPUT_F — CPU配置的值，由cfg_clb_in_sel_h选择可直接作为CLB模块clb_bdry_in_h的输入 保护模式：无 加载方式：动态加载
    [4] INPUT_E — CPU配置的值，由cfg_clb_in_sel_h选择可直接作为CLB模块clb_bdry_in_h的输入 保护模式：无 加载方式：动态加载
    [3] INPUT_D — CPU配置的值，由cfg_clb_in_sel_h选择可直接作为CLB模块clb_bdry_in_h的输入 保护模式：无 加载方式：动态加载
    [2] INPUT_C — CPU配置的值，由cfg_clb_in_sel_c选择可直接作为CLB模块clb_bdry_in_c的输入 保护模式：无 加载方式：动态加载
    [1] INPUT_B — CPU配置的值，由cfg_clb_in_sel_b选择可直接作为CLB模块clb_bdry_in_b的输入 保护模式：无 加载方式：动态加载
    [0] INPUT_A — CPU配置的值，由cfg_clb_in_sel_a选择可直接作为CLB模块clb_bdry_in_a的输入 保护模式：无 加载方式：动态加载
  0xC4 OUT
    [31:0] EN — CLB输出信号使能，对于每一bit： 'b0 = peripheral 信号pass through原来的路径 'b1 =CLB边界输出替换对应的外设信号，发送往外设原先的目的地； 保护模式：无 加载方式：静态加载
  0xC8 OUT_1D
    [9:0] SEL — 边界输出是否打一拍后发送到对应目的地；对于每一bit： 'b0 = 每个tile的输出bypass，发送往全局信号列表/XBARs; 'b1 = 每个tile的输出打一拍后，发送往全局信号列表/XBARs 保护模式：无 加载方式：静态加载
  0xCC OUTLUT_PIPE0
    [4n] SEL{n} (n=0..7) — 发送到OUTPUTLUT{n}的CSB选择前信号是否打拍； 信号包含： fsm0_output，lut0_output，fsm1_output lut1_output，fsm2_output，lut2_output 'b0 =bypass，适用异步信号直接发送到IO; 'b1 = 打一拍；同步信号需要选择该项； 保护模式：无 加载方式：静态加载
  0xD0 GLB_MUX
    [27:21] SEL_D — INPUT_D 7比特Global MUX选择信号，参见本地信号多路复用表 保护模式：LOCK 加载方式：静态加载
    [20:14] SEL_C — INPUT_C 7比特Global MUX选择信号，参见本地信号多路复用表 保护模式：LOCK 加载方式：静态加载
    [13:7] SEL_B — INPUT_B 7比特Global MUX选择信号，参见本地信号多路复用表 保护模式：LOCK 加载方式：静态加载
    [6:0] SEL_A — INPUT_A 7比特Global MUX选择信号，参见全局信号多路复用表 保护模式：LOCK 加载方式：静态加载
  0xD4 GLB_MUX_SEL
    [27:21] H — INPUT_H 7比特Global MUX选择信号，参见本地信号多路复用表 保护模式：LOCK 加载方式：静态加载
    [20:14] G — INPUT_G 7比特Global MUX选择信号，参见本地信号多路复用表 保护模式：LOCK 加载方式：静态加载
    [13:7] F — INPUT_F 7比特Global MUX选择信号，参见本地信号多路复用表 保护模式：LOCK 加载方式：静态加载
    [6:0] E — INPUT_E 7比特Global MUX选择信号，参见全局信号多路复用表 保护模式：LOCK 加载方式：静态加载
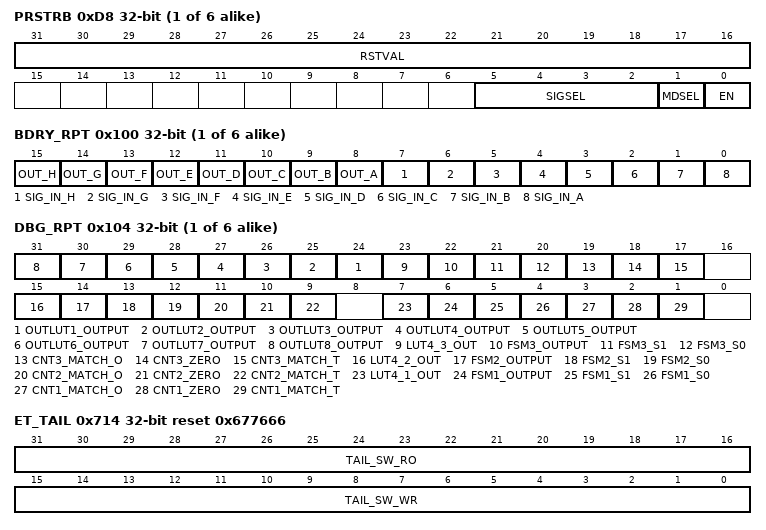
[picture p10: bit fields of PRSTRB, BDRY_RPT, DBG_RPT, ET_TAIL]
  0xD8 PRSTRB
    [31:16] RSTVAL — 当PRSTRB模块内16bit计数器达到该值时复位到0； 保护模式：LOCK 加载方式：静态加载
    [5:2] SIGSEL — MUX选择信号，选取计数器某一比特信号，例如 'b0000 = 选择计数器比特0，实际上对应时钟2分频 'b0001 = 选择计数器比特1，实际上对应时钟4分频 ... 'b1111 = 选择计数器比特15，实际上对应时钟2^16分频 保护模式：LOCK 加载方式：静态加载
    [1] MDSEL — clk/strobe选择信号 'b0 = prescale模块输出strobe。当计数器值等于prescale_value时产生strobe; 'b1 = 输出tap信号选择的计数器某位bit信号 保护模式：LOCK 加载方式：静态加载
    [0] EN — 使能预分频clk/strobe发生器 16 位计数器用于产生strobe或向 CLB CELL 发送选定的计数器位bit。通过一个 LCL_IN MUX 端口把strobe/预分频clk发送到 Tile，Tile 逻辑可根据需要选用。 clk/strobe选择信号 'b0 = prstrb模块输出为0；同时模块内计数器暂复位为0 'b1 = 输出tap信号选择的计数器某位bit信号 保护模式：LOCK 加载方式：静态加载
  0xDC HLC_INST_ADDR_RPT ro
    [4:0] VALUE — 用于读取instruction mem 值的地址指针 保护模式：无
  0xE0 HLC_INST_RPT ro
    [11:0] VALUE — HLC模块内根据读指针上报对应地址的指令值；
  0xE4 HLC_GNRL_RA_RPT ro
    [31:0] DBG — HLC模块内通用寄存器R1上报；
  0xE8 HLC_GNRL_RB_RPT ro
    [31:0] DBG — HLC模块内通用寄存器R2上报；
  0xEC HLC_GNRL_RC_RPT ro
    [31:0] DBG — HLC模块内通用寄存器R3上报；
  0xF0 HLC_GNRL_RD_RPT ro
    [31:0] DBG — HLC模块内通用寄存器R4上报；
  {0xF0+4j} CNT{j}_VAL_RPT ro (j=1..3)
    [31:0] DBG — CNT{j}计数器值上报；
  0x100 BDRY_RPT ro
    [15] OUT_H — CLB_AOC模块边界输出h上报
    [14] OUT_G — CLB_AOC模块边界输出g上报
    [13] OUT_F — CLB_AOC模块边界输出f上报
    [12] OUT_E — CLB_AOC模块边界输出e上报
    [11] OUT_D — CLB_AOC模块边界输出d上报
    [10] OUT_C — CLB_AOC模块边界输出c上报
    [9] OUT_B — CLB_AOC模块边界输出b上报
    [8] OUT_A — CLB_AOC模块边界输出a上报
    [7] SIG_IN_H — CLB_INPUT_FLT边界输入h上报；
    [6] SIG_IN_G — CLB_INPUT_FLT边界输入g上报；
    [5] SIG_IN_F — CLB_INPUT_FLT边界输入f上报；
    [4] SIG_IN_E — CLB_INPUT_FLT边界输入e上报；
    [3] SIG_IN_D — CLB_INPUT_FLT边界输入d上报；
    [2] SIG_IN_C — CLB_INPUT_FLT边界输入c上报；
    [1] SIG_IN_B — CLB_INPUT_FLT边界输入b上报；
    [0] SIG_IN_A — CLB_INPUT_FLT边界输入a上报；
  0x104 DBG_RPT ro
    [n+23] OUTLUT{n}_OUTPUT (n=1..8) — CLB_OUTLUT{n}模块输出上报
    [23] LUT4_3_OUT — CLB_LUT4_3 输出上报；
    [22] FSM3_OUTPUT — CLB_FSM3输出上报
    [21] FSM3_S1 — CLB_FSM3状态寄存器S1上报
    [20] FSM3_S0 — CLB_FSM3状态寄存器S0上报
    [19] CNT3_MATCH_O — CLB_CNT3 MATCH1事件上报
    [18] CNT3_ZERO — CLB_CNT3 ZERO事件上报
    [17] CNT3_MATCH_T — CLB_CNT3 MATCH2事件上报
    [15] LUT4_2_OUT — CLB_LUT4_2 输出上报；
    [14] FSM2_OUTPUT — CLB_FSM2输出上报
    [13] FSM2_S1 — CLB_FSM2状态寄存器S1上报
    [12] FSM2_S0 — CLB_FSM2状态寄存器S0上报
    [11] CNT2_MATCH_O — CLB_CNT2 MATCH1事件上报
    [10] CNT2_ZERO — CLB_CNT2 ERO事件上报
    [9] CNT2_MATCH_T — CLB_CNT2 MATCH2事件上报
    [7] LUT4_1_OUT — CLB_LUT4_1 输出上报；
    [6] FSM1_OUTPUT — CLB_FSM1输出上报
    [5] FSM1_S1 — CLB_FSM1状态寄存器S1上报
    [4] FSM1_S0 — CLB_FSM1状态寄存器S0上报
    [3] CNT1_MATCH_O — CLB_CNT1 MATCH1事件上报
    [2] CNT1_ZERO — CLB_CNT1 ZERO事件上报
    [1] CNT1_MATCH_T — CLB_CNT1 MATCH2事件上报
  0x108 PUSH_A_RPT ro
    [31:0] VALUE — hlc2fifo，用于HLC模块PUSH指令
  0x10C PUSH_B_RPT ro
    [31:0] VALUE — hlc2fifo，用于HLC模块PUSH指令
  0x110 PUSH_C_RPT ro
    [31:0] VALUE — hlc2fifo，用于HLC模块PUSH指令
  0x114 PUSH_D_RPT ro
    [31:0] VALUE — hlc2fifo，用于HLC模块PUSH指令
  0x118 PULL_A
    [31:0] VALUE — fifo2hlc，用于HLC模块PULL指令
  0x11C PULL_B
    [31:0] VALUE — fifo2hlc fifo2hlc，用于HLC模块PULL指令
  0x120 PULL_C
    [31:0] VALUE — fifo2hlc fifo2hlc，用于HLC模块PULL指令
  0x124 PULL_D
    [31:0] VALUE — fifo2hlc fifo2hlc，用于HLC模块PULL指令
  0x128 INT_TAG_RPT
    [5:0] VALUE — 上报HLC模块的INTR指令6bit中断TAG；软件写1清；
0x70C SPITRANS_MUX
  [2:0] SEL — SPItrans模式下，现有设计CLB只和一个SPI有接口，该sel信号在顶层选择其中的一组作为CLB输出到SPI的信号； 2'd0: clb_tile1作为输出信号； 2'd1: clb_tile2作为输出信号； 2'd2: clb_tile3作为输出信号； 2'd3: clb_tile4作为输出信号； 2'd4: clb_tile5作为输出信号； 2'd4: clb_tile6作为输出信号；
0x710 LOCK
  [15:0] KEY — 该16bits值作为软件读写权限的一个key；只有当该值被写入0x5a5a时，被保护的寄存器才允许被写入。 保护模式：EALLOW 加载方式：动态加载
0x714 ET_TAIL reset 0x677666
  [31:16] TAIL_SW_RO ro — 软件测试读写寄存器，硬件无访问
  [15:0] TAIL_SW_WR — 软件只读上报寄存器，硬件无访问,CLB的ASICII 码表示
